VERSION ""

NS_ :

BS_:

BU_: arttest vera

BO_ 123 vera_inputs: 1 arttest
 SG_ obstacleDetected : 0|1@1+ (1,0) [0|1] ""  vera

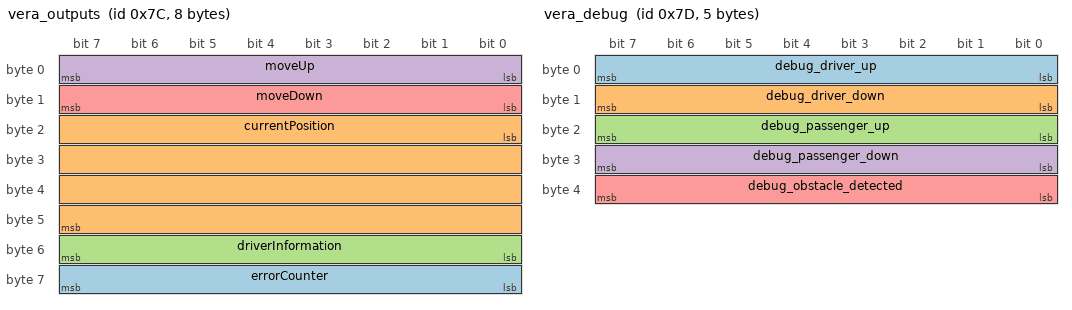
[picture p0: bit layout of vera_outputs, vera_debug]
BO_ 124 vera_outputs: 8 vera
 SG_ errorCounter : 56|8@1+ (1,0) [0|0] ""  arttest
 SG_ currentPosition : 16|32@1- (1,0) [0|0] ""  arttest
 SG_ driverInformation : 48|8@1+ (1,0) [0|0] ""  arttest
 SG_ moveUp : 0|8@1+ (1,0) [0|0] "" Vector__XXX
 SG_ moveDown : 8|8@1+ (1,0) [0|0] "" Vector__XXX

BO_ 125 vera_debug: 5 vera
 SG_ debug_driver_up : 0|8@1+ (1,0) [0|0] ""  arttest
 SG_ debug_driver_down : 8|8@1+ (1,0) [0|0] ""  arttest
 SG_ debug_passenger_up : 16|8@1+ (1,0) [0|0] ""  arttest
 SG_ debug_passenger_down : 24|8@1+ (1,0) [0|0] ""  arttest
 SG_ debug_obstacle_detected : 32|8@1+ (1,0) [0|0] ""  arttest

CM_ SG_ 123 obstacleDetected "Gives information about obstacle detection for the Arttest WindowControl demo project.";
SIG_VALTYPE_ 124 currentPosition : 1;
